VERSION "J35_6AT"

NS_ :

BS_:

BU_: PCM UNKNOWN

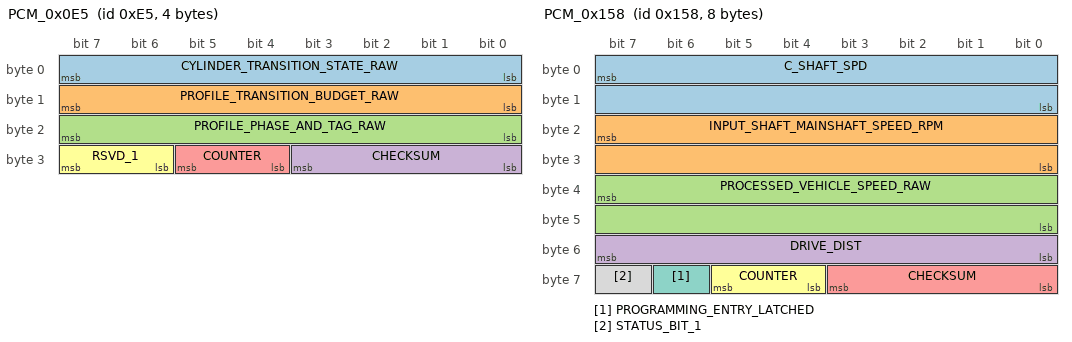
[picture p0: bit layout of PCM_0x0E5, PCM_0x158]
BO_ 229 PCM_0x0E5: 4 PCM
 SG_ CYLINDER_TRANSITION_STATE_RAW : 0|8@1+ (1,0) [0|255] ""  UNKNOWN
 SG_ PROFILE_TRANSITION_BUDGET_RAW : 8|8@1+ (1,0) [0|255] ""  UNKNOWN
 SG_ PROFILE_PHASE_AND_TAG_RAW : 16|8@1+ (1,0) [0|255] ""  UNKNOWN
 SG_ CHECKSUM : 24|4@1+ (1,0) [0|15] ""  UNKNOWN
 SG_ COUNTER : 28|2@1+ (1,0) [0|3] ""  UNKNOWN
 SG_ RSVD_1 : 30|2@1+ (1,0) [0|3] ""  UNKNOWN

BO_ 316 PCM_0x13C: 8 PCM
 SG_ TORQUE_ESTIMATE : 7|16@0- (1,0) [-32768|32767] "raw"  UNKNOWN
 SG_ TORQUE_TARGET : 23|16@0- (1,0) [-32768|32767] "raw"  UNKNOWN
 SG_ APP_SENSOR : 32|8@1+ (0.39215686274509803,0) [0|100] "%"  UNKNOWN
 SG_ TORQUE_STATE : 40|2@1+ (1,0) [0|3] ""  UNKNOWN
 SG_ RSVD_1 : 42|2@1+ (1,0) [0|3] ""  UNKNOWN
 SG_ RSVD_2 : 44|1@1+ (1,0) [0|1] ""  UNKNOWN
 SG_ FRAME_1AA_WINDOW_LATCH : 45|1@1+ (1,0) [0|1] ""  UNKNOWN
 SG_ START_PHASE_LATCH : 46|1@1+ (1,0) [0|1] ""  UNKNOWN
 SG_ DTC_STATUS_7_LATCH : 47|1@1+ (1,0) [0|1] ""  UNKNOWN
 SG_ RSVD_3 : 48|2@1+ (1,0) [0|3] ""  UNKNOWN
 SG_ CLUTCH_ENGAGEMENT_INFORMATION_CRUISE_CONTROL : 50|1@1+ (1,0) [0|1] ""  UNKNOWN
 SG_ CONTROL_GUARD_RAW : 51|1@1+ (1,0) [0|1] ""  UNKNOWN
 SG_ RSVD_4 : 52|4@1+ (1,0) [0|15] ""  UNKNOWN
 SG_ CHECKSUM : 56|4@1+ (1,0) [0|15] ""  UNKNOWN
 SG_ COUNTER : 60|2@1+ (1,0) [0|3] ""  UNKNOWN
 SG_ RSVD_5 : 62|1@1+ (1,0) [0|1] ""  UNKNOWN
 SG_ FRAME_1AA_INVALID_OR_FALLBACK_STATE_TBD : 63|1@1+ (1,0) [0|1] ""  UNKNOWN
VAL_ 316 CLUTCH_ENGAGEMENT_INFORMATION_CRUISE_CONTROL 0 "ON" 1 "OFF" ;
VAL_ 316 TORQUE_STATE 0 "NORMAL" 1 "VSA_CONTROL_CANDIDATE" 2 "FUEL_CUT" 3 "UNKNOWN" ;

BO_ 344 PCM_0x158: 8 PCM
 SG_ C_SHAFT_SPD : 7|16@0+ (0.01,0) [0|655.35] ""  UNKNOWN
 SG_ INPUT_SHAFT_MAINSHAFT_SPEED_RPM : 23|16@0+ (1,0) [0|65535] "raw"  UNKNOWN
 SG_ PROCESSED_VEHICLE_SPEED_RAW : 39|16@0+ (0.01,0) [0|655.35] ""  UNKNOWN
 SG_ DRIVE_DIST : 48|8@1+ (1,0) [0|255] "raw"  UNKNOWN
 SG_ CHECKSUM : 56|4@1+ (1,0) [0|15] ""  UNKNOWN
 SG_ COUNTER : 60|2@1+ (1,0) [0|3] ""  UNKNOWN
 SG_ PROGRAMMING_ENTRY_LATCHED : 62|1@1+ (1,0) [0|1] ""  UNKNOWN
 SG_ STATUS_BIT_1 : 63|1@1+ (1,0) [0|1] ""  UNKNOWN

BO_ 380 PCM_0x17C: 8 PCM
 SG_ APP_SENSOR : 0|8@1+ (0.39215686274509803,0) [0|100] "%"  UNKNOWN
 SG_ THROTTLE_ABOVE_IDLE_CODE : 8|8@1+ (0.4,0) [0|102] "deg"  UNKNOWN
 SG_ ENGINE_SPEED : 23|16@0+ (1,0) [0|65535] "rpm"  UNKNOWN
 SG_ BRAKE_SWITCH : 32|1@1+ (1,0) [0|1] ""  UNKNOWN
 SG_ CRUISE_CANCEL_EVENT : 33|1@1+ (1,0) [0|1] ""  UNKNOWN
 SG_ CRUISE_FAULT_SPEED_INHIBIT : 34|1@1+ (1,0) [0|1] ""  UNKNOWN
 SG_ CRUISE_ENGAGED : 35|1@1+ (1,0) [0|1] ""  UNKNOWN
 SG_ MIL : 36|1@1+ (1,0) [0|1] ""  UNKNOWN
 SG_ MIL_STATUS : 37|1@1+ (1,0) [0|1] ""  UNKNOWN
 SG_ CRUISE_INDICATOR : 38|1@1+ (1,0) [0|1] ""  UNKNOWN
 SG_ GAS_PEDAL_PRESSED : 39|1@1+ (1,0) [0|1] ""  UNKNOWN
 SG_ RSVD_1 : 40|2@1+ (1,0) [0|3] ""  UNKNOWN
 SG_ ACCEL_PEDAL_FAULT : 42|1@1+ (1,0) [0|1] ""  UNKNOWN
 SG_ RSVD_2 : 43|5@1+ (1,0) [0|31] ""  UNKNOWN
 SG_ RSVD_3 : 48|5@1+ (1,0) [0|31] ""  UNKNOWN
 SG_ CRUISE_BRAKE_SW_IDLE_STOP_SW : 53|1@1+ (1,0) [0|1] ""  UNKNOWN
 SG_ CRUISE_TRANS_REQUEST_WIRE : 54|2@1+ (1,0) [0|3] ""  UNKNOWN
 SG_ CHECKSUM : 56|4@1+ (1,0) [0|15] ""  UNKNOWN
 SG_ COUNTER : 60|2@1+ (1,0) [0|3] ""  UNKNOWN
 SG_ RSVD_4 : 62|1@1+ (1,0) [0|1] ""  UNKNOWN
 SG_ DTC_GROUP_WARNING_REQUESTED : 63|1@1+ (1,0) [0|1] ""  UNKNOWN
VAL_ 380 CRUISE_BRAKE_SW_IDLE_STOP_SW 0 "CLOSE" 1 "OPEN" ;
VAL_ 380 CRUISE_INDICATOR 0 "OFF" 1 "ON" ;
VAL_ 380 MIL_STATUS 0 "OFF" 1 "ON" ;
VAL_ 380 MIL 0 "OFF" 1 "ON" ;
VAL_ 380 BRAKE_SWITCH 0 "OFF" 1 "ON" ;

BO_ 392 PCM_0x188: 6 PCM
 SG_ SHIFT_CONTROL_CODE_A_RAW : 0|4@1+ (1,0) [0|15] ""  UNKNOWN
 SG_ TRANSMISSION_LATCH_RAW : 4|1@1+ (1,0) [0|1] ""  UNKNOWN
 SG_ CONDITIONED_GEAR_CODE_RAW : 5|3@1+ (1,0) [0|7] ""  UNKNOWN
 SG_ SHIFT_CONTROL_CODE_B_RAW : 8|3@1+ (1,0) [0|7] ""  UNKNOWN
 SG_ LED_C : 11|1@1+ (1,0) [0|1] ""  UNKNOWN
 SG_ LED_B : 12|1@1+ (1,0) [0|1] ""  UNKNOWN
 SG_ LED_A : 13|1@1+ (1,0) [0|1] ""  UNKNOWN
 SG_ SIGNED_CODE_SPILL_D1_RAW : 14|2@1+ (1,0) [0|3] ""  UNKNOWN
 SG_ SELECTOR_INDICATOR_RAW : 16|1@1+ (1,0) [0|1] ""  UNKNOWN
 SG_ TRANSMISSION_STATE_RAW : 17|1@1+ (1,0) [0|1] ""  UNKNOWN
 SG_ TRANSMISSION_QUALIFICATION_RAW : 18|1@1+ (1,0) [0|1] ""  UNKNOWN
 SG_ MANUAL_MODE_INDICATOR : 19|1@1+ (1,0) [0|1] ""  UNKNOWN
 SG_ INDICATOR_FAULT_RAW : 20|1@1+ (1,0) [0|1] ""  UNKNOWN
 SG_ TRANSMISSION_DIAGNOSTIC_LATCH_RAW : 21|1@1+ (1,0) [0|1] ""  UNKNOWN
 SG_ COMMUNICATION_STATUS_RAW : 22|1@1+ (1,0) [0|1] ""  UNKNOWN
 SG_ SHIFT_INDICATOR_CONTROL_RAW : 23|1@1+ (1,0) [0|1] ""  UNKNOWN
 SG_ A_T_P_SWITCH : 24|1@1+ (1,0) [0|1] ""  UNKNOWN
 SG_ A_T_R_SWITCH : 25|1@1+ (1,0) [0|1] ""  UNKNOWN
 SG_ A_T_N_SWITCH : 26|1@1+ (1,0) [0|1] ""  UNKNOWN
 SG_ A_T_D_SWITCH : 27|1@1+ (1,0) [0|1] ""  UNKNOWN
 SG_ RSVD_1 : 28|1@1+ (1,0) [0|1] ""  UNKNOWN
 SG_ A_T_D3_SWITCH : 29|1@1+ (1,0) [0|1] ""  UNKNOWN
 SG_ A_T_2_SWITCH_OR_A_T_L_SWITCH : 30|1@1+ (1,0) [0|1] ""  UNKNOWN
 SG_ A_T_1_SWITCH : 31|1@1+ (1,0) [0|1] ""  UNKNOWN
 SG_ SHIFT_POSITION_DISPLAY_CODE_RAW : 32|4@1+ (1,0) [0|15] ""  UNKNOWN
 SG_ A_T_S_SWITCH : 36|1@1+ (1,0) [0|1] ""  UNKNOWN
 SG_ SERVICE_RESET_ACK_RAW : 37|1@1+ (1,0) [0|1] ""  UNKNOWN
 SG_ SERVICE_DUE_RAW : 38|1@1+ (1,0) [0|1] ""  UNKNOWN
 SG_ SIGNED_CODE_SPILL_D4_RAW : 39|1@1+ (1,0) [0|1] ""  UNKNOWN
 SG_ CHECKSUM : 40|4@1+ (1,0) [0|15] ""  UNKNOWN
 SG_ COUNTER : 44|2@1+ (1,0) [0|3] ""  UNKNOWN
 SG_ QUALIFIED_TRANSMISSION_STATUS_RAW : 46|1@1+ (1,0) [0|1] ""  UNKNOWN
 SG_ RSVD_2 : 47|1@1+ (1,0) [0|1] ""  UNKNOWN
VAL_ 392 A_T_S_SWITCH 0 "OFF" 1 "ON" ;
VAL_ 392 A_T_1_SWITCH 0 "OFF" 1 "ON" ;
VAL_ 392 A_T_D3_SWITCH 0 "OFF" 1 "ON" ;
VAL_ 392 A_T_D_SWITCH 0 "OFF" 1 "ON" ;
VAL_ 392 A_T_N_SWITCH 0 "OFF" 1 "ON" ;
VAL_ 392 A_T_R_SWITCH 0 "OFF" 1 "ON" ;
VAL_ 392 A_T_P_SWITCH 0 "OFF" 1 "ON" ;
VAL_ 392 MANUAL_MODE_INDICATOR 0 "OFF" 1 "ON" ;
VAL_ 392 LED_A 0 "OFF" 1 "ON" ;
VAL_ 392 LED_B 0 "OFF" 1 "ON" ;
VAL_ 392 LED_C 0 "OFF" 1 "ON" ;

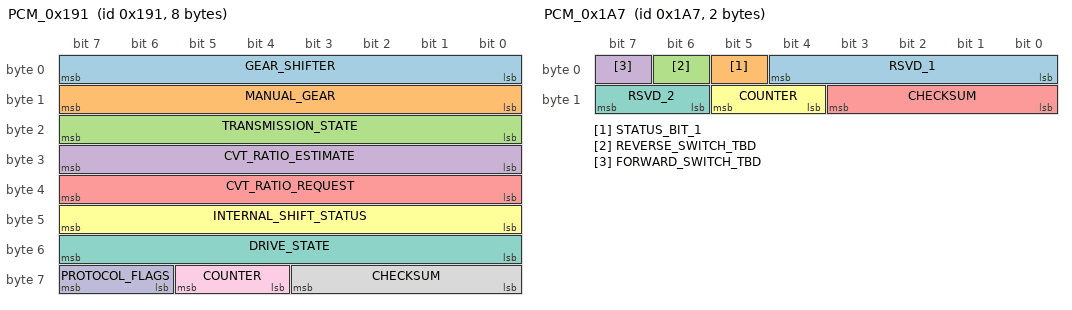
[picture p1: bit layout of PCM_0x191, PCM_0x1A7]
BO_ 401 PCM_0x191: 8 PCM
 SG_ GEAR_SHIFTER : 0|8@1+ (1,0) [0|255] ""  UNKNOWN
 SG_ MANUAL_GEAR : 8|8@1+ (1,0) [0|255] ""  UNKNOWN
 SG_ TRANSMISSION_STATE : 16|8@1+ (1,0) [0|255] ""  UNKNOWN
 SG_ CVT_RATIO_ESTIMATE : 24|8@1+ (1,0) [0|255] ""  UNKNOWN
 SG_ CVT_RATIO_REQUEST : 32|8@1+ (1,0) [0|255] ""  UNKNOWN
 SG_ INTERNAL_SHIFT_STATUS : 40|8@1+ (1,0) [0|255] ""  UNKNOWN
 SG_ DRIVE_STATE : 48|8@1+ (1,0) [0|255] ""  UNKNOWN
 SG_ CHECKSUM : 56|4@1+ (1,0) [0|15] ""  UNKNOWN
 SG_ COUNTER : 60|2@1+ (1,0) [0|3] ""  UNKNOWN
 SG_ PROTOCOL_FLAGS : 62|2@1+ (1,0) [0|3] ""  UNKNOWN

BO_ 423 PCM_0x1A7: 2 PCM
 SG_ RSVD_1 : 0|5@1+ (1,0) [0|31] ""  UNKNOWN
 SG_ STATUS_BIT_1 : 5|1@1+ (1,0) [0|1] ""  UNKNOWN
 SG_ REVERSE_SWITCH_TBD : 6|1@1+ (1,0) [0|1] ""  UNKNOWN
 SG_ FORWARD_SWITCH_TBD : 7|1@1+ (1,0) [0|1] ""  UNKNOWN
 SG_ CHECKSUM : 8|4@1+ (1,0) [0|15] ""  UNKNOWN
 SG_ COUNTER : 12|2@1+ (1,0) [0|3] ""  UNKNOWN
 SG_ RSVD_2 : 14|2@1+ (1,0) [0|3] ""  UNKNOWN

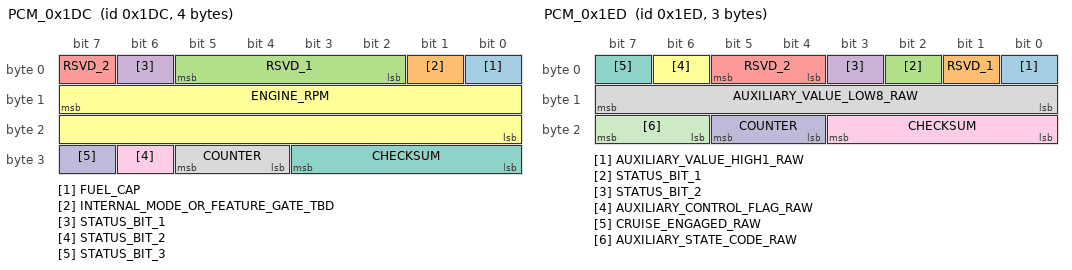
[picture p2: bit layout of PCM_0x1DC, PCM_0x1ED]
BO_ 476 PCM_0x1DC: 4 PCM
 SG_ FUEL_CAP : 0|1@1+ (1,0) [0|1] ""  UNKNOWN
 SG_ INTERNAL_MODE_OR_FEATURE_GATE_TBD : 1|1@1+ (1,0) [0|1] ""  UNKNOWN
 SG_ RSVD_1 : 2|4@1+ (1,0) [0|15] ""  UNKNOWN
 SG_ STATUS_BIT_1 : 6|1@1+ (1,0) [0|1] ""  UNKNOWN
 SG_ RSVD_2 : 7|1@1+ (1,0) [0|1] ""  UNKNOWN
 SG_ ENGINE_RPM : 15|16@0+ (1,0) [0|65535] "rpm"  UNKNOWN
 SG_ CHECKSUM : 24|4@1+ (1,0) [0|15] ""  UNKNOWN
 SG_ COUNTER : 28|2@1+ (1,0) [0|3] ""  UNKNOWN
 SG_ STATUS_BIT_2 : 30|1@1+ (1,0) [0|1] ""  UNKNOWN
 SG_ STATUS_BIT_3 : 31|1@1+ (1,0) [0|1] ""  UNKNOWN
VAL_ 476 FUEL_CAP 0 "CLOSE" 1 "OPEN" ;

BO_ 493 PCM_0x1ED: 3 PCM
 SG_ AUXILIARY_VALUE_HIGH1_RAW : 0|1@1+ (1,0) [0|1] ""  UNKNOWN
 SG_ RSVD_1 : 1|1@1+ (1,0) [0|1] ""  UNKNOWN
 SG_ STATUS_BIT_1 : 2|1@1+ (1,0) [0|1] ""  UNKNOWN
 SG_ STATUS_BIT_2 : 3|1@1+ (1,0) [0|1] ""  UNKNOWN
 SG_ RSVD_2 : 4|2@1+ (1,0) [0|3] ""  UNKNOWN
 SG_ AUXILIARY_CONTROL_FLAG_RAW : 6|1@1+ (1,0) [0|1] ""  UNKNOWN
 SG_ CRUISE_ENGAGED_RAW : 7|1@1+ (1,0) [0|1] ""  UNKNOWN
 SG_ AUXILIARY_VALUE_LOW8_RAW : 8|8@1+ (1,0) [0|255] ""  UNKNOWN
 SG_ CHECKSUM : 16|4@1+ (1,0) [0|15] ""  UNKNOWN
 SG_ COUNTER : 20|2@1+ (1,0) [0|3] ""  UNKNOWN
 SG_ AUXILIARY_STATE_CODE_RAW : 22|2@1+ (1,0) [0|3] ""  UNKNOWN

BO_ 800 BCM_0x320: 8 PCM
 SG_ RSVD_1 : 0|6@1+ (1,0) [0|63] ""  UNKNOWN
 SG_ ENGINE_STATE_CODE_TBD : 6|2@1+ (1,0) [0|3] ""  UNKNOWN
 SG_ STATUS_BIT_1 : 8|1@1+ (1,0) [0|1] ""  UNKNOWN
 SG_ STATUS_BIT_2 : 9|1@1+ (1,0) [0|1] ""  UNKNOWN
 SG_ RSVD_2 : 10|4@1+ (1,0) [0|15] ""  UNKNOWN
 SG_ STATUS_BIT_3 : 14|1@1+ (1,0) [0|1] ""  UNKNOWN
 SG_ RSVD_3 : 15|1@1+ (1,0) [0|1] ""  UNKNOWN
 SG_ UNKNOWN_1 : 16|3@1+ (1,0) [0|7] ""  UNKNOWN
 SG_ SIGNED_CAP_OUT_OF_DOMAIN_HIGH_BITS_B2_TBD : 19|3@1+ (1,0) [0|7] ""  UNKNOWN
 SG_ STATUS_BIT_4 : 22|1@1+ (1,0) [0|1] ""  UNKNOWN
 SG_ SIGNED_CAP_OUT_OF_DOMAIN_SIGN_BIT_B2_TBD : 23|1@1+ (1,0) [0|1] ""  UNKNOWN
 SG_ RSVD_4 : 24|8@1+ (1,0) [0|255] ""  UNKNOWN
 SG_ RSVD_5 : 32|7@1+ (1,0) [0|127] ""  UNKNOWN
 SG_ STATUS_BIT_5 : 39|1@1+ (1,0) [0|1] ""  UNKNOWN
 SG_ UNKNOWN_2 : 40|3@1+ (1,0) [0|7] ""  UNKNOWN
 SG_ UNKNOWN_3 : 43|3@1+ (1,0) [0|7] ""  UNKNOWN
 SG_ SIGNED_CAP_OUT_OF_DOMAIN_HIGH_BITS_B5_TBD : 46|2@1+ (1,0) [0|3] ""  UNKNOWN
 SG_ STATUS_BIT_6 : 48|1@1+ (1,0) [0|1] ""  UNKNOWN
 SG_ RSVD_6 : 49|2@1+ (1,0) [0|3] ""  UNKNOWN
 SG_ STATUS_BIT_7 : 51|1@1+ (1,0) [0|1] ""  UNKNOWN
 SG_ RSVD_7 : 52|4@1+ (1,0) [0|15] ""  UNKNOWN
 SG_ CHECKSUM : 56|4@1+ (1,0) [0|15] ""  UNKNOWN
 SG_ COUNTER : 60|2@1+ (1,0) [0|3] ""  UNKNOWN
 SG_ STATUS_BIT_8 : 62|1@1+ (1,0) [0|1] ""  UNKNOWN
 SG_ STATUS_BIT_9 : 63|1@1+ (1,0) [0|1] ""  UNKNOWN

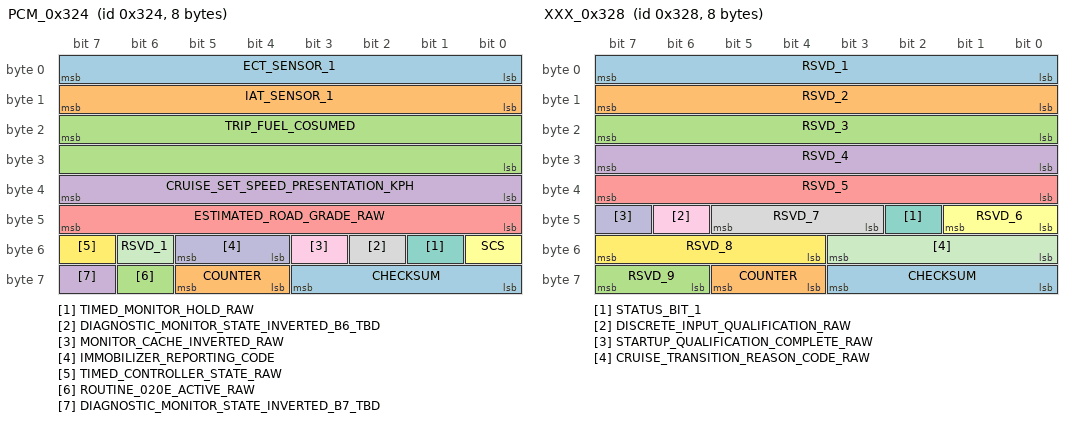
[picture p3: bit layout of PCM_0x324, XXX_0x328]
BO_ 804 PCM_0x324: 8 PCM
 SG_ ECT_SENSOR_1 : 0|8@1+ (1,-40) [-40|215] "degC"  UNKNOWN
 SG_ IAT_SENSOR_1 : 8|8@1+ (1,-40) [-40|215] "degC"  UNKNOWN
 SG_ TRIP_FUEL_COSUMED : 23|16@0+ (1,0) [0|65535] ""  UNKNOWN
 SG_ CRUISE_SET_SPEED_PRESENTATION_KPH : 32|8@1+ (1,0) [0|255] "raw"  UNKNOWN
 SG_ ESTIMATED_ROAD_GRADE_RAW : 40|8@1- (0.125,0) [-16|15.875] ""  UNKNOWN
 SG_ SCS : 48|1@1+ (1,0) [0|1] ""  UNKNOWN
 SG_ TIMED_MONITOR_HOLD_RAW : 49|1@1+ (1,0) [0|1] ""  UNKNOWN
 SG_ DIAGNOSTIC_MONITOR_STATE_INVERTED_B6_TBD : 50|1@1+ (1,0) [0|1] ""  UNKNOWN
 SG_ MONITOR_CACHE_INVERTED_RAW : 51|1@1+ (1,0) [0|1] ""  UNKNOWN
 SG_ IMMOBILIZER_REPORTING_CODE : 52|2@1+ (1,0) [0|3] ""  UNKNOWN
 SG_ RSVD_1 : 54|1@1+ (1,0) [0|1] ""  UNKNOWN
 SG_ TIMED_CONTROLLER_STATE_RAW : 55|1@1+ (1,0) [0|1] ""  UNKNOWN
 SG_ CHECKSUM : 56|4@1+ (1,0) [0|15] ""  UNKNOWN
 SG_ COUNTER : 60|2@1+ (1,0) [0|3] ""  UNKNOWN
 SG_ ROUTINE_020E_ACTIVE_RAW : 62|1@1+ (1,0) [0|1] ""  UNKNOWN
 SG_ DIAGNOSTIC_MONITOR_STATE_INVERTED_B7_TBD : 63|1@1+ (1,0) [0|1] ""  UNKNOWN
VAL_ 804 IMMOBILIZER_REPORTING_CODE 0 "COMPLETE_ACCEPTED" 1 "INCOMPLETE" 2 "COMPLETE_NOT_ACCEPTED" ;
VAL_ 804 SCS 0 "OPEN" 1 "SHORT" ;
VAL_ 804 IAT_SENSOR_1 255 "INVALID" ;
VAL_ 804 ECT_SENSOR_1 255 "INVALID" ;

BO_ 808 XXX_0x328: 8 PCM
 SG_ RSVD_1 : 0|8@1+ (1,0) [0|255] ""  UNKNOWN
 SG_ RSVD_2 : 8|8@1+ (1,0) [0|255] ""  UNKNOWN
 SG_ RSVD_3 : 16|8@1+ (1,0) [0|255] ""  UNKNOWN
 SG_ RSVD_4 : 24|8@1+ (1,0) [0|255] ""  UNKNOWN
 SG_ RSVD_5 : 32|8@1+ (1,0) [0|255] ""  UNKNOWN
 SG_ RSVD_6 : 40|2@1+ (1,0) [0|3] ""  UNKNOWN
 SG_ STATUS_BIT_1 : 42|1@1+ (1,0) [0|1] ""  UNKNOWN
 SG_ RSVD_7 : 43|3@1+ (1,0) [0|7] ""  UNKNOWN
 SG_ DISCRETE_INPUT_QUALIFICATION_RAW : 46|1@1+ (1,0) [0|1] ""  UNKNOWN
 SG_ STARTUP_QUALIFICATION_COMPLETE_RAW : 47|1@1+ (1,0) [0|1] ""  UNKNOWN
 SG_ CRUISE_TRANSITION_REASON_CODE_RAW : 48|4@1+ (1,0) [0|15] ""  UNKNOWN
 SG_ RSVD_8 : 52|4@1+ (1,0) [0|15] ""  UNKNOWN
 SG_ CHECKSUM : 56|4@1+ (1,0) [0|15] ""  UNKNOWN
 SG_ COUNTER : 60|2@1+ (1,0) [0|3] ""  UNKNOWN
 SG_ RSVD_9 : 62|2@1+ (1,0) [0|3] ""  UNKNOWN

BO_ 892 PCM_0x37C: 8 PCM
 SG_ UNKNOWN_1 : 0|8@1+ (1,0) [0|255] ""  UNKNOWN
 SG_ UNKNOWN_2 : 8|8@1+ (1,0) [0|255] ""  UNKNOWN
 SG_ UNKNOWN_3 : 16|8@1+ (1,0) [0|255] ""  UNKNOWN
 SG_ UNKNOWN_4 : 24|8@1+ (1,0) [0|255] ""  UNKNOWN
 SG_ RSVD_1 : 32|8@1+ (1,0) [0|255] ""  UNKNOWN
 SG_ UNKNOWN_5 : 40|7@1+ (1,0) [0|127] ""  UNKNOWN
 SG_ STATUS_BIT_1 : 47|1@1+ (1,0) [0|1] ""  UNKNOWN
 SG_ STATUS_BIT_2 : 48|1@1+ (1,0) [0|1] ""  UNKNOWN
 SG_ STATUS_BIT_3 : 49|1@1+ (1,0) [0|1] ""  UNKNOWN
 SG_ STATUS_BIT_4 : 50|1@1+ (1,0) [0|1] ""  UNKNOWN
 SG_ STATUS_BIT_5 : 51|1@1+ (1,0) [0|1] ""  UNKNOWN
 SG_ STATUS_BIT_6 : 52|1@1+ (1,0) [0|1] ""  UNKNOWN
 SG_ STATUS_BIT_7 : 53|1@1+ (1,0) [0|1] ""  UNKNOWN
 SG_ STATUS_BIT_8 : 54|1@1+ (1,0) [0|1] ""  UNKNOWN
 SG_ STATUS_BIT_9 : 55|1@1+ (1,0) [0|1] ""  UNKNOWN
 SG_ CHECKSUM : 56|4@1+ (1,0) [0|15] ""  UNKNOWN
 SG_ COUNTER : 60|2@1+ (1,0) [0|3] ""  UNKNOWN
 SG_ RSVD_2 : 62|1@1+ (1,0) [0|1] ""  UNKNOWN
 SG_ STATUS_BIT_10 : 63|1@1+ (1,0) [0|1] ""  UNKNOWN

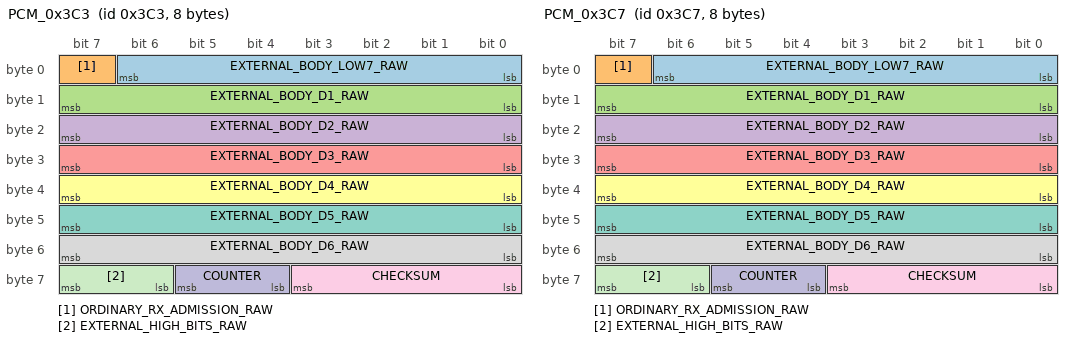
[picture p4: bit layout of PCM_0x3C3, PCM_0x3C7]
BO_ 963 PCM_0x3C3: 8 PCM
 SG_ EXTERNAL_BODY_LOW7_RAW : 0|7@1+ (1,0) [0|0] ""  UNKNOWN
 SG_ ORDINARY_RX_ADMISSION_RAW : 7|1@1+ (1,0) [0|0] ""  UNKNOWN
 SG_ EXTERNAL_BODY_D1_RAW : 8|8@1+ (1,0) [0|0] ""  UNKNOWN
 SG_ EXTERNAL_BODY_D2_RAW : 16|8@1+ (1,0) [0|0] ""  UNKNOWN
 SG_ EXTERNAL_BODY_D3_RAW : 24|8@1+ (1,0) [0|0] ""  UNKNOWN
 SG_ EXTERNAL_BODY_D4_RAW : 32|8@1+ (1,0) [0|0] ""  UNKNOWN
 SG_ EXTERNAL_BODY_D5_RAW : 40|8@1+ (1,0) [0|0] ""  UNKNOWN
 SG_ EXTERNAL_BODY_D6_RAW : 48|8@1+ (1,0) [0|0] ""  UNKNOWN
 SG_ CHECKSUM : 56|4@1+ (1,0) [0|0] ""  UNKNOWN
 SG_ COUNTER : 60|2@1+ (1,0) [0|0] ""  UNKNOWN
 SG_ EXTERNAL_HIGH_BITS_RAW : 62|2@1+ (1,0) [0|0] ""  UNKNOWN

BO_ 967 PCM_0x3C7: 8 PCM
 SG_ EXTERNAL_BODY_LOW7_RAW : 0|7@1+ (1,0) [0|0] ""  UNKNOWN
 SG_ ORDINARY_RX_ADMISSION_RAW : 7|1@1+ (1,0) [0|0] ""  UNKNOWN
 SG_ EXTERNAL_BODY_D1_RAW : 8|8@1+ (1,0) [0|0] ""  UNKNOWN
 SG_ EXTERNAL_BODY_D2_RAW : 16|8@1+ (1,0) [0|0] ""  UNKNOWN
 SG_ EXTERNAL_BODY_D3_RAW : 24|8@1+ (1,0) [0|0] ""  UNKNOWN
 SG_ EXTERNAL_BODY_D4_RAW : 32|8@1+ (1,0) [0|0] ""  UNKNOWN
 SG_ EXTERNAL_BODY_D5_RAW : 40|8@1+ (1,0) [0|0] ""  UNKNOWN
 SG_ EXTERNAL_BODY_D6_RAW : 48|8@1+ (1,0) [0|0] ""  UNKNOWN
 SG_ CHECKSUM : 56|4@1+ (1,0) [0|0] ""  UNKNOWN
 SG_ COUNTER : 60|2@1+ (1,0) [0|0] ""  UNKNOWN
 SG_ EXTERNAL_HIGH_BITS_RAW : 62|2@1+ (1,0) [0|0] ""  UNKNOWN

BO_ 983 PCM_0x3D7: 8 PCM
 SG_ MULTIPLEX_HEADER : 0|8@1+ (1,0) [0|255] ""  UNKNOWN
 SG_ RETAINED_BANK_A_CODE_WORD_0_PAGE_0 m0 : 15|16@0+ (1,0) [0|65535] ""  UNKNOWN
 SG_ RETAINED_BANK_A_CODE_WORD_0_PAGE_1 m1 : 15|16@0+ (1,0) [0|65535] ""  UNKNOWN
 SG_ RETAINED_BANK_A_CODE_WORD_1_PAGE_0 m0 : 31|16@0+ (1,0) [0|65535] ""  UNKNOWN
 SG_ RETAINED_BANK_A_CODE_WORD_1_PAGE_1 m1 : 31|16@0+ (1,0) [0|65535] ""  UNKNOWN
 SG_ RETAINED_BANK_A_CODE_WORD_2_PAGE_0 m0 : 47|16@0+ (1,0) [0|65535] ""  UNKNOWN
 SG_ RETAINED_BANK_A_CODE_WORD_2_PAGE_1 m1 : 47|16@0+ (1,0) [0|65535] ""  UNKNOWN
 SG_ CHECKSUM : 56|4@1+ (1,0) [0|15] ""  UNKNOWN
 SG_ COUNTER : 60|2@1+ (1,0) [0|3] ""  UNKNOWN
 SG_ PAGE_INDEX M : 62|1@1+ (1,0) [0|1] ""  UNKNOWN
 SG_ PROTOCOL_BIT7 : 63|1@1+ (1,0) [0|1] ""  UNKNOWN
VAL_ 983 PAGE_INDEX 0 "SLOTS0_TO2" 1 "SLOTS3_TO5" ;
SG_MUL_VAL_ 983 RETAINED_BANK_A_CODE_WORD_0_PAGE_0 PAGE_INDEX 0-0;
SG_MUL_VAL_ 983 RETAINED_BANK_A_CODE_WORD_0_PAGE_1 PAGE_INDEX 1-1;
SG_MUL_VAL_ 983 RETAINED_BANK_A_CODE_WORD_1_PAGE_0 PAGE_INDEX 0-0;
SG_MUL_VAL_ 983 RETAINED_BANK_A_CODE_WORD_1_PAGE_1 PAGE_INDEX 1-1;
SG_MUL_VAL_ 983 RETAINED_BANK_A_CODE_WORD_2_PAGE_0 PAGE_INDEX 0-0;
SG_MUL_VAL_ 983 RETAINED_BANK_A_CODE_WORD_2_PAGE_1 PAGE_INDEX 1-1;

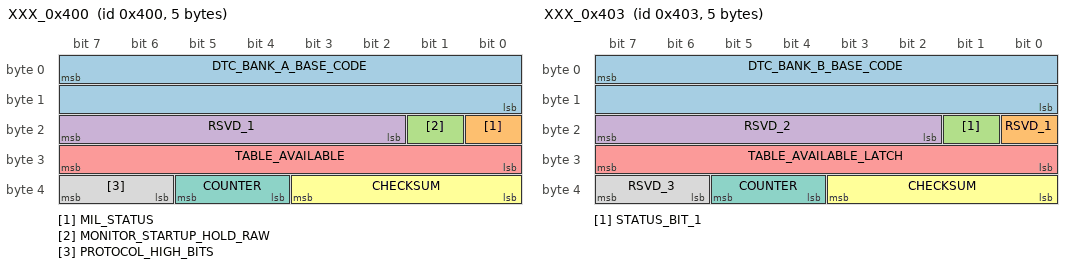
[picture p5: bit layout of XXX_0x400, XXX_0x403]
BO_ 1024 XXX_0x400: 5 PCM
 SG_ DTC_BANK_A_BASE_CODE : 7|16@0+ (1,0) [0|65535] ""  UNKNOWN
 SG_ MIL_STATUS : 16|1@1+ (1,0) [0|1] ""  UNKNOWN
 SG_ MONITOR_STARTUP_HOLD_RAW : 17|1@1+ (1,0) [0|1] ""  UNKNOWN
 SG_ RSVD_1 : 18|6@1+ (1,0) [0|63] ""  UNKNOWN
 SG_ TABLE_AVAILABLE : 24|8@1+ (1,0) [0|255] ""  UNKNOWN
 SG_ CHECKSUM : 32|4@1+ (1,0) [0|15] ""  UNKNOWN
 SG_ COUNTER : 36|2@1+ (1,0) [0|3] ""  UNKNOWN
 SG_ PROTOCOL_HIGH_BITS : 38|2@1+ (1,0) [0|3] ""  UNKNOWN
VAL_ 1024 MIL_STATUS 0 "OFF" 1 "ON" ;

BO_ 1027 XXX_0x403: 5 PCM
 SG_ DTC_BANK_B_BASE_CODE : 7|16@0+ (1,0) [0|65535] ""  UNKNOWN
 SG_ RSVD_1 : 16|1@1+ (1,0) [0|1] ""  UNKNOWN
 SG_ STATUS_BIT_1 : 17|1@1+ (1,0) [0|1] ""  UNKNOWN
 SG_ RSVD_2 : 18|6@1+ (1,0) [0|63] ""  UNKNOWN
 SG_ TABLE_AVAILABLE_LATCH : 24|8@1+ (1,0) [0|255] ""  UNKNOWN
 SG_ CHECKSUM : 32|4@1+ (1,0) [0|15] ""  UNKNOWN
 SG_ COUNTER : 36|2@1+ (1,0) [0|3] ""  UNKNOWN
 SG_ RSVD_3 : 38|2@1+ (1,0) [0|3] ""  UNKNOWN

BO_ 1036 XXX_0x40C: 8 PCM
 SG_ MULTIPLEX_PAGE M : 0|4@1+ (1,0) [0|15] ""  UNKNOWN
 SG_ MULTIPLEX_GROUP : 4|2@1+ (1,0) [0|3] ""  UNKNOWN
 SG_ DIAGNOSTIC_EVENT_STATE : 6|2@1+ (1,0) [0|3] ""  UNKNOWN
 SG_ RSVD_1 m0 : 8|8@1+ (1,0) [0|255] ""  UNKNOWN
 SG_ P01_VIN_CHARACTER_1_B1_RAW m1 : 8|8@1+ (1,0) [0|255] ""  UNKNOWN
 SG_ P02_VIN_CHARACTER_7_B1_RAW m2 : 8|8@1+ (1,0) [0|255] ""  UNKNOWN
 SG_ P03_VIN_CHARACTER_13_B1_RAW m3 : 8|8@1+ (1,0) [0|255] ""  UNKNOWN
 SG_ P04_VARIANTCONFIGBYTE1_B1_RAW m4 : 8|8@1+ (1,0) [0|255] ""  UNKNOWN
 SG_ P05_ENGINE_SPEED m5 : 15|16@0+ (0.25,0) [0|16383.75] "rpm"  UNKNOWN
 SG_ P06_IAT_SENSOR_VOLTAGE_B1_RAW m6 : 8|8@1+ (0.0196078431372549,0) [0|5] "V"  UNKNOWN
 SG_ P07_VEHICLE_SPEED_B1_RAW m7 : 8|8@1+ (1,0) [0|255] "km/h"  UNKNOWN
 SG_ P08_APP_SENSOR m8 : 15|16@0+ (0.005,0) [0|327.675] "%"  UNKNOWN
 SG_ P09_TARGET_TH_VLV m9 : 15|16@0+ (0.005,0) [0|327.675] "deg"  UNKNOWN
 SG_ P0A_AF_SENSOR_B1 m10 : 15|16@0+ (1,0) [0|65535] ""  UNKNOWN
 SG_ UNKNOWN_1 m11 : 8|8@1+ (1,0) [0|255] ""  UNKNOWN
 SG_ P0C_AF_FB_ST_FUEL_TRIM_B2 m12 : 8|8@1+ (0.0078125,0) [0|1.9921875] "ratio"  UNKNOWN
 SG_ P0D_EGR_VALVE_POSITION_SENSOR_EGR_VLS m13 : 8|8@1+ (1,0) [0|255] ""  UNKNOWN
 SG_ P0E_MASSAIRFLOW m14 : 15|16@0+ (0.01,0) [0|655.35] "g/s"  UNKNOWN
 SG_ P0F_FUELTANKLEVELINPUT_B1_RAW m15 : 8|8@1+ (0.39215686274509803,0) [0|100] "%"  UNKNOWN
 SG_ P00_DIAGNOSTIC_EVENT_CACHE_WORD m0 : 23|16@0+ (1,0) [0|65535] ""  UNKNOWN
 SG_ P01_VIN_CHARACTER_2_B2_RAW m1 : 16|8@1+ (1,0) [0|255] ""  UNKNOWN
 SG_ P02_VIN_CHARACTER_8_B2_RAW m2 : 16|8@1+ (1,0) [0|255] ""  UNKNOWN
 SG_ P03_VIN_CHARACTER_14_B2_RAW m3 : 16|8@1+ (1,0) [0|255] ""  UNKNOWN
 SG_ P04_VARIANTCONFIGBYTE2_B2_RAW m4 : 16|8@1+ (1,0) [0|255] ""  UNKNOWN
 SG_ P06_INTAKE_AIR_TEMPERATURE_B2_RAW m6 : 16|8@1+ (1,-40) [-40|215] "degC"  UNKNOWN
 SG_ P07_CALCULATEDENGINELOAD_B2_RAW m7 : 16|8@1+ (0.39215686274509803,0) [0|100] "%"  UNKNOWN
 SG_ P0B_HO2S_S2_B1 m11 : 16|8@1+ (0.0196078431372549,0) [0|5] "V"  UNKNOWN
 SG_ P0C_AF_FB_AVE_LT_FUEL_TRIM_B2 m12 : 16|8@1+ (0.0078125,0) [0|1.9921875] "ratio"  UNKNOWN
 SG_ RSVD_2 m13 : 16|8@1+ (1,0) [0|255] ""  UNKNOWN
 SG_ RSVD_3 m15 : 16|8@1+ (1,0) [0|255] ""  UNKNOWN
 SG_ P01_VIN_CHARACTER_3_B3_RAW m1 : 24|8@1+ (1,0) [0|255] ""  UNKNOWN
 SG_ P02_VIN_CHARACTER_9_B3_RAW m2 : 24|8@1+ (1,0) [0|255] ""  UNKNOWN
 SG_ P03_VIN_CHARACTER_15_B3_RAW m3 : 24|8@1+ (1,0) [0|255] ""  UNKNOWN
 SG_ P04_VARIANTCONFIGBYTE3_B3_RAW m4 : 24|8@1+ (1,0) [0|255] ""  UNKNOWN
 SG_ P05_THROTTLEPOSITION_B3_RAW m5 : 24|8@1+ (0.39215686274509803,0) [0|100] "%"  UNKNOWN
 SG_ P06_MAP_SENSOR_VOLTAGE_B3_RAW m6 : 24|8@1+ (0.0196078431372549,0) [0|5] "V"  UNKNOWN
 SG_ P07_SPARK_ADVANCE m7 : 24|8@1+ (0.5,-64) [-64|63.5] "deg"  UNKNOWN
 SG_ P08_TP_SENSOR_1 m8 : 24|8@1+ (0.0196078431372549,0) [0|5] "V"  UNKNOWN
 SG_ UNKNOWN_2 m9 : 24|8@1+ (1,0) [0|255] ""  UNKNOWN
 SG_ P0A_AF_LAMBDA_B1 m10 : 31|16@0+ (3.0517578125e-05,0) [0|1.999969482421875] "ratio"  UNKNOWN
 SG_ P0B_AF_SENSOR_B2 m11 : 31|16@0+ (1,0) [0|65535] ""  UNKNOWN
 SG_ UNKNOWN_3 m12 : 24|8@1+ (1,0) [0|255] ""  UNKNOWN
 SG_ RSVD_4 m13 : 24|8@1+ (1,0) [0|255] ""  UNKNOWN
 SG_ RSVD_5 m14 : 24|8@1+ (1,0) [0|255] ""  UNKNOWN
 SG_ RSVD_6 m15 : 24|8@1+ (1,0) [0|255] ""  UNKNOWN
 SG_ UNKNOWN_4 m0 : 32|8@1+ (1,0) [0|255] ""  UNKNOWN
 SG_ P01_VIN_CHARACTER_4_B4_RAW m1 : 32|8@1+ (1,0) [0|255] ""  UNKNOWN
 SG_ P02_VIN_CHARACTER_10_B4_RAW m2 : 32|8@1+ (1,0) [0|255] ""  UNKNOWN
 SG_ P03_VIN_CHARACTER_16_B4_RAW m3 : 32|8@1+ (1,0) [0|255] ""  UNKNOWN
 SG_ P04_VARIANTCONFIGBYTE4_B4_RAW m4 : 32|8@1+ (1,0) [0|255] ""  UNKNOWN
 SG_ P05_RELATIVETHROTTLEPOSITION_B4_RAW m5 : 32|8@1+ (0.39215686274509803,0) [0|100] "%"  UNKNOWN
 SG_ P06_MANIFOLD_ABSOLUTE_PRESSURE_B4_RAW m6 : 32|8@1+ (1,0) [0|255] "kPa"  UNKNOWN
 SG_ P07_CONTROL_MODULE_VOLTAGE_DECIVOLT_RAW m7 : 32|8@1+ (0.1,0) [0|25.5] "V"  UNKNOWN
 SG_ P08_TP_SENSOR_2 m8 : 32|8@1+ (0.0196078431372549,0) [0|5] "V"  UNKNOWN
 SG_ UNKNOWN_5 m9 : 32|8@1+ (1,0) [0|255] ""  UNKNOWN
 SG_ P0C_HO2S_S2_B2 m12 : 32|8@1+ (0.0196078431372549,0) [0|5] "V"  UNKNOWN
 SG_ P0D_MAF_SENSOR m13 : 32|8@1+ (0.0196078431372549,0) [0|5] "V"  UNKNOWN
 SG_ P0E_RUNTIMESINCEENGINESTART m14 : 39|16@0+ (1,0) [0|65535] "s"  UNKNOWN
 SG_ RSVD_7 m15 : 32|8@1+ (1,0) [0|255] ""  UNKNOWN
 SG_ RSVD_8 m0 : 40|8@1+ (1,0) [0|255] ""  UNKNOWN
 SG_ P01_VIN_CHARACTER_5_B5_RAW m1 : 40|8@1+ (1,0) [0|255] ""  UNKNOWN
 SG_ P02_VIN_CHARACTER_11_B5_RAW m2 : 40|8@1+ (1,0) [0|255] ""  UNKNOWN
 SG_ P03_VIN_CHARACTER_17_B5_RAW m3 : 40|8@1+ (1,0) [0|255] ""  UNKNOWN
 SG_ P04_VARIANTCONFIGBYTE5_B5_RAW m4 : 40|8@1+ (1,0) [0|255] ""  UNKNOWN
 SG_ P05_ECT_SENSOR_VOLTAGE_B5_RAW m5 : 40|8@1+ (0.0196078431372549,0) [0|5] "V"  UNKNOWN
 SG_ P06_BARO_SENSOR_VOLTAGE_B5_RAW m6 : 40|8@1+ (0.0196078431372549,0) [0|5] "V"  UNKNOWN
 SG_ P07_APP_SENSOR_A_VOLTAGE_B5_RAW m7 : 40|8@1+ (0.0196078431372549,0) [0|5] "V"  UNKNOWN
 SG_ P08_THROTTLE_VLV m8 : 47|16@0+ (0.005,0) [0|327.675] "deg"  UNKNOWN
 SG_ P09_IDLE_TARGET_TH m9 : 47|16@0+ (0.005,0) [0|327.675] "deg"  UNKNOWN
 SG_ P0A_SHORTTERMFUELTRIMBANK1_B5_RAW m10 : 40|8@1+ (0.78125,-100) [-100|99.21875] "%"  UNKNOWN
 SG_ P0B_AF_LAMBDA_B2 m11 : 47|16@0+ (3.0517578125e-05,0) [0|1.999969482421875] "ratio"  UNKNOWN
 SG_ P0C_F_INJECTOR m12 : 47|16@0+ (0.004,0) [0|262.14] "ms"  UNKNOWN
 SG_ RSVD_9 m13 : 40|8@1+ (1,0) [0|255] ""  UNKNOWN
 SG_ RSVD_10 m15 : 40|8@1+ (1,0) [0|255] ""  UNKNOWN
 SG_ RSVD_11 m0 : 48|8@1+ (1,0) [0|255] ""  UNKNOWN
 SG_ P01_VIN_CHARACTER_6_B6_RAW m1 : 48|8@1+ (1,0) [0|255] ""  UNKNOWN
 SG_ P02_VIN_CHARACTER_12_B6_RAW m2 : 48|8@1+ (1,0) [0|255] ""  UNKNOWN
 SG_ UNKNOWN_6 m3 : 48|8@1+ (1,0) [0|255] ""  UNKNOWN
 SG_ RSVD_12 m4 : 48|8@1+ (1,0) [0|255] ""  UNKNOWN
 SG_ P05_ENGINE_COOLANT_TEMPERATURE_B6_RAW m5 : 48|8@1+ (1,-40) [-40|215] "degC"  UNKNOWN
 SG_ P06_BAROMETRICPRESSURE_B6_RAW m6 : 48|8@1+ (1,0) [0|255] "kPa"  UNKNOWN
 SG_ P07_APP_SENSOR_B_VOLTAGE_B6_RAW m7 : 48|8@1+ (0.0196078431372549,0) [0|5] "V"  UNKNOWN
 SG_ P0A_LONGTERMFUELTRIMBANK1_B6_RAW m10 : 48|8@1+ (0.78125,-100) [-100|99.21875] "%"  UNKNOWN
 SG_ RSVD_13 m13 : 48|8@1+ (1,0) [0|255] ""  UNKNOWN
 SG_ P0E_COMMANDEDEVAPORATIVEPURGE_B6_RAW m14 : 48|8@1+ (0.39215686274509803,0) [0|100] "%"  UNKNOWN
 SG_ RSVD_14 m15 : 48|8@1+ (1,0) [0|255] ""  UNKNOWN
 SG_ CHECKSUM : 56|4@1+ (1,0) [0|15] ""  UNKNOWN
 SG_ COUNTER : 60|2@1+ (1,0) [0|3] ""  UNKNOWN
 SG_ DIAGNOSTIC_STATUS_FLAG6 : 62|1@1+ (1,0) [0|1] ""  UNKNOWN
 SG_ DIAGNOSTIC_STATUS_FLAG7 : 63|1@1+ (1,0) [0|1] ""  UNKNOWN
SG_MUL_VAL_ 1036 RSVD_1 MULTIPLEX_PAGE 0-0;
SG_MUL_VAL_ 1036 P01_VIN_CHARACTER_1_B1_RAW MULTIPLEX_PAGE 1-1;
SG_MUL_VAL_ 1036 P02_VIN_CHARACTER_7_B1_RAW MULTIPLEX_PAGE 2-2;
SG_MUL_VAL_ 1036 P03_VIN_CHARACTER_13_B1_RAW MULTIPLEX_PAGE 3-3;
SG_MUL_VAL_ 1036 P04_VARIANTCONFIGBYTE1_B1_RAW MULTIPLEX_PAGE 4-4;
SG_MUL_VAL_ 1036 P05_ENGINE_SPEED MULTIPLEX_PAGE 5-5;
SG_MUL_VAL_ 1036 P06_IAT_SENSOR_VOLTAGE_B1_RAW MULTIPLEX_PAGE 6-6;
SG_MUL_VAL_ 1036 P07_VEHICLE_SPEED_B1_RAW MULTIPLEX_PAGE 7-7;
SG_MUL_VAL_ 1036 P08_APP_SENSOR MULTIPLEX_PAGE 8-8;
SG_MUL_VAL_ 1036 P09_TARGET_TH_VLV MULTIPLEX_PAGE 9-9;
SG_MUL_VAL_ 1036 P0A_AF_SENSOR_B1 MULTIPLEX_PAGE 10-10;
SG_MUL_VAL_ 1036 UNKNOWN_1 MULTIPLEX_PAGE 11-11;
SG_MUL_VAL_ 1036 P0C_AF_FB_ST_FUEL_TRIM_B2 MULTIPLEX_PAGE 12-12;
SG_MUL_VAL_ 1036 P0D_EGR_VALVE_POSITION_SENSOR_EGR_VLS MULTIPLEX_PAGE 13-13;
SG_MUL_VAL_ 1036 P0E_MASSAIRFLOW MULTIPLEX_PAGE 14-14;
SG_MUL_VAL_ 1036 P0F_FUELTANKLEVELINPUT_B1_RAW MULTIPLEX_PAGE 15-15;
SG_MUL_VAL_ 1036 P00_DIAGNOSTIC_EVENT_CACHE_WORD MULTIPLEX_PAGE 0-0;
SG_MUL_VAL_ 1036 P01_VIN_CHARACTER_2_B2_RAW MULTIPLEX_PAGE 1-1;
SG_MUL_VAL_ 1036 P02_VIN_CHARACTER_8_B2_RAW MULTIPLEX_PAGE 2-2;
SG_MUL_VAL_ 1036 P03_VIN_CHARACTER_14_B2_RAW MULTIPLEX_PAGE 3-3;
SG_MUL_VAL_ 1036 P04_VARIANTCONFIGBYTE2_B2_RAW MULTIPLEX_PAGE 4-4;
SG_MUL_VAL_ 1036 P06_INTAKE_AIR_TEMPERATURE_B2_RAW MULTIPLEX_PAGE 6-6;
SG_MUL_VAL_ 1036 P07_CALCULATEDENGINELOAD_B2_RAW MULTIPLEX_PAGE 7-7;
SG_MUL_VAL_ 1036 P0B_HO2S_S2_B1 MULTIPLEX_PAGE 11-11;
SG_MUL_VAL_ 1036 P0C_AF_FB_AVE_LT_FUEL_TRIM_B2 MULTIPLEX_PAGE 12-12;
SG_MUL_VAL_ 1036 RSVD_2 MULTIPLEX_PAGE 13-13;
SG_MUL_VAL_ 1036 RSVD_3 MULTIPLEX_PAGE 15-15;
SG_MUL_VAL_ 1036 P01_VIN_CHARACTER_3_B3_RAW MULTIPLEX_PAGE 1-1;
SG_MUL_VAL_ 1036 P02_VIN_CHARACTER_9_B3_RAW MULTIPLEX_PAGE 2-2;
SG_MUL_VAL_ 1036 P03_VIN_CHARACTER_15_B3_RAW MULTIPLEX_PAGE 3-3;
SG_MUL_VAL_ 1036 P04_VARIANTCONFIGBYTE3_B3_RAW MULTIPLEX_PAGE 4-4;
SG_MUL_VAL_ 1036 P05_THROTTLEPOSITION_B3_RAW MULTIPLEX_PAGE 5-5;
SG_MUL_VAL_ 1036 P06_MAP_SENSOR_VOLTAGE_B3_RAW MULTIPLEX_PAGE 6-6;
SG_MUL_VAL_ 1036 P07_SPARK_ADVANCE MULTIPLEX_PAGE 7-7;
SG_MUL_VAL_ 1036 P08_TP_SENSOR_1 MULTIPLEX_PAGE 8-8;
SG_MUL_VAL_ 1036 UNKNOWN_2 MULTIPLEX_PAGE 9-9;
SG_MUL_VAL_ 1036 P0A_AF_LAMBDA_B1 MULTIPLEX_PAGE 10-10;
SG_MUL_VAL_ 1036 P0B_AF_SENSOR_B2 MULTIPLEX_PAGE 11-11;
SG_MUL_VAL_ 1036 UNKNOWN_3 MULTIPLEX_PAGE 12-12;
SG_MUL_VAL_ 1036 RSVD_4 MULTIPLEX_PAGE 13-13;
SG_MUL_VAL_ 1036 RSVD_5 MULTIPLEX_PAGE 14-14;
SG_MUL_VAL_ 1036 RSVD_6 MULTIPLEX_PAGE 15-15;
SG_MUL_VAL_ 1036 UNKNOWN_4 MULTIPLEX_PAGE 0-0;
SG_MUL_VAL_ 1036 P01_VIN_CHARACTER_4_B4_RAW MULTIPLEX_PAGE 1-1;
SG_MUL_VAL_ 1036 P02_VIN_CHARACTER_10_B4_RAW MULTIPLEX_PAGE 2-2;
SG_MUL_VAL_ 1036 P03_VIN_CHARACTER_16_B4_RAW MULTIPLEX_PAGE 3-3;
SG_MUL_VAL_ 1036 P04_VARIANTCONFIGBYTE4_B4_RAW MULTIPLEX_PAGE 4-4;
SG_MUL_VAL_ 1036 P05_RELATIVETHROTTLEPOSITION_B4_RAW MULTIPLEX_PAGE 5-5;
SG_MUL_VAL_ 1036 P06_MANIFOLD_ABSOLUTE_PRESSURE_B4_RAW MULTIPLEX_PAGE 6-6;
SG_MUL_VAL_ 1036 P07_CONTROL_MODULE_VOLTAGE_DECIVOLT_RAW MULTIPLEX_PAGE 7-7;
SG_MUL_VAL_ 1036 P08_TP_SENSOR_2 MULTIPLEX_PAGE 8-8;
SG_MUL_VAL_ 1036 UNKNOWN_5 MULTIPLEX_PAGE 9-9;
SG_MUL_VAL_ 1036 P0C_HO2S_S2_B2 MULTIPLEX_PAGE 12-12;
SG_MUL_VAL_ 1036 P0D_MAF_SENSOR MULTIPLEX_PAGE 13-13;
SG_MUL_VAL_ 1036 P0E_RUNTIMESINCEENGINESTART MULTIPLEX_PAGE 14-14;
SG_MUL_VAL_ 1036 RSVD_7 MULTIPLEX_PAGE 15-15;
SG_MUL_VAL_ 1036 RSVD_8 MULTIPLEX_PAGE 0-0;
SG_MUL_VAL_ 1036 P01_VIN_CHARACTER_5_B5_RAW MULTIPLEX_PAGE 1-1;
SG_MUL_VAL_ 1036 P02_VIN_CHARACTER_11_B5_RAW MULTIPLEX_PAGE 2-2;
SG_MUL_VAL_ 1036 P03_VIN_CHARACTER_17_B5_RAW MULTIPLEX_PAGE 3-3;
SG_MUL_VAL_ 1036 P04_VARIANTCONFIGBYTE5_B5_RAW MULTIPLEX_PAGE 4-4;
SG_MUL_VAL_ 1036 P05_ECT_SENSOR_VOLTAGE_B5_RAW MULTIPLEX_PAGE 5-5;
SG_MUL_VAL_ 1036 P06_BARO_SENSOR_VOLTAGE_B5_RAW MULTIPLEX_PAGE 6-6;
SG_MUL_VAL_ 1036 P07_APP_SENSOR_A_VOLTAGE_B5_RAW MULTIPLEX_PAGE 7-7;
SG_MUL_VAL_ 1036 P08_THROTTLE_VLV MULTIPLEX_PAGE 8-8;
SG_MUL_VAL_ 1036 P09_IDLE_TARGET_TH MULTIPLEX_PAGE 9-9;
SG_MUL_VAL_ 1036 P0A_SHORTTERMFUELTRIMBANK1_B5_RAW MULTIPLEX_PAGE 10-10;
SG_MUL_VAL_ 1036 P0B_AF_LAMBDA_B2 MULTIPLEX_PAGE 11-11;
SG_MUL_VAL_ 1036 P0C_F_INJECTOR MULTIPLEX_PAGE 12-12;
SG_MUL_VAL_ 1036 RSVD_9 MULTIPLEX_PAGE 13-13;
SG_MUL_VAL_ 1036 RSVD_10 MULTIPLEX_PAGE 15-15;
SG_MUL_VAL_ 1036 RSVD_11 MULTIPLEX_PAGE 0-0;
SG_MUL_VAL_ 1036 P01_VIN_CHARACTER_6_B6_RAW MULTIPLEX_PAGE 1-1;
SG_MUL_VAL_ 1036 P02_VIN_CHARACTER_12_B6_RAW MULTIPLEX_PAGE 2-2;
SG_MUL_VAL_ 1036 UNKNOWN_6 MULTIPLEX_PAGE 3-3;
SG_MUL_VAL_ 1036 RSVD_12 MULTIPLEX_PAGE 4-4;
SG_MUL_VAL_ 1036 P05_ENGINE_COOLANT_TEMPERATURE_B6_RAW MULTIPLEX_PAGE 5-5;
SG_MUL_VAL_ 1036 P06_BAROMETRICPRESSURE_B6_RAW MULTIPLEX_PAGE 6-6;
SG_MUL_VAL_ 1036 P07_APP_SENSOR_B_VOLTAGE_B6_RAW MULTIPLEX_PAGE 7-7;
SG_MUL_VAL_ 1036 P0A_LONGTERMFUELTRIMBANK1_B6_RAW MULTIPLEX_PAGE 10-10;
SG_MUL_VAL_ 1036 RSVD_13 MULTIPLEX_PAGE 13-13;
SG_MUL_VAL_ 1036 P0E_COMMANDEDEVAPORATIVEPURGE_B6_RAW MULTIPLEX_PAGE 14-14;
SG_MUL_VAL_ 1036 RSVD_14 MULTIPLEX_PAGE 15-15;

BO_ 1039 XXX_0x40F: 8 PCM
 SG_ MULTIPLEX_PAGE M : 0|4@1+ (1,0) [0|15] ""  UNKNOWN
 SG_ MULTIPLEX_GROUP : 4|2@1+ (1,0) [0|3] ""  UNKNOWN
 SG_ DIAGNOSTIC_EVENT_STATE : 6|2@1+ (1,0) [0|3] ""  UNKNOWN
 SG_ UNKNOWN_1 m0 : 8|8@1+ (1,0) [0|255] ""  UNKNOWN
 SG_ P01_CONFIG_BYTE_1_RAW m1 : 8|8@1+ (1,0) [0|255] ""  UNKNOWN
 SG_ P02_ENGINE_SPEED m2 : 8|8@1+ (50,0) [0|12750] "rpm"  UNKNOWN
 SG_ P03_ENGINE_COOLANT_TEMPERATURE m3 : 8|8@1+ (1,-40) [-40|215] "degC"  UNKNOWN
 SG_ P04_BARO_SENSOR_V m4 : 8|8@1+ (0.0196,0) [0|4.998] "V"  UNKNOWN
 SG_ P05_INPUT_SHAFT_MAINSHAFT_SPEED_RPM m5 : 15|16@0+ (1,0) [0|65535] "rpm"  UNKNOWN
 SG_ P06_A_T_C_P_C_SOL_VLV_A_ACTUAL m6 : 8|8@1+ (0.005,0) [0|1.2750000000000001] "A"  UNKNOWN
 SG_ P07_LINE_PRESSURE_SOL_VLV_A m7 : 8|1@1+ (1,0) [0|1] ""  UNKNOWN
 SG_ RSVD_1 m8 : 8|8@1+ (1,0) [0|255] ""  UNKNOWN
 SG_ P07_SHIFT_SOLENOID_VALVE_G m7 : 9|1@1+ (1,0) [0|1] ""  UNKNOWN
 SG_ P07_SHIFT_SOLENOID_VALVE_F m7 : 10|1@1+ (1,0) [0|1] ""  UNKNOWN
 SG_ P07_A_T_SHIFT_SOL_VLV_E m7 : 11|1@1+ (1,0) [0|1] ""  UNKNOWN
 SG_ P07_A_T_SHIFT_SOL_VLV_D m7 : 12|1@1+ (1,0) [0|1] ""  UNKNOWN
 SG_ P07_A_T_SHIFT_SOL_VLV_C m7 : 13|1@1+ (1,0) [0|1] ""  UNKNOWN
 SG_ P07_A_T_SHIFT_SOL_VLV_B m7 : 14|1@1+ (1,0) [0|1] ""  UNKNOWN
 SG_ P07_A_T_SHIFT_SOL_VLV_A m7 : 15|1@1+ (1,0) [0|1] ""  UNKNOWN
 SG_ UNKNOWN_2 m0 : 23|16@0+ (1,0) [0|65535] ""  UNKNOWN
 SG_ P01_CONFIG_BYTE_2_RAW m1 : 16|8@1+ (1,0) [0|255] ""  UNKNOWN
 SG_ P02_OUTPUT_SHAFT_COUNTER_SHAFT_SPEED m2 : 16|8@1+ (1,0) [0|255] "km/h"  UNKNOWN
 SG_ P03_BATTERY_VOLTAGE m3 : 16|8@1+ (0.1,0) [0|25.5] "V"  UNKNOWN
 SG_ P04_ATMOSPHERIC_PRESSURE m4 : 16|8@1+ (1,0) [0|255] "kPa"  UNKNOWN
 SG_ P06_A_T_C_P_C_SOL_VLV_B_COMMAND m6 : 16|8@1+ (0.005,0) [0|1.2750000000000001] "A"  UNKNOWN
 SG_ P07_ATF_TEMP_SENSOR_V m7 : 16|8@1+ (0.0196,0) [0|4.998] "V"  UNKNOWN
 SG_ RSVD_2 m8 : 16|8@1+ (1,0) [0|255] ""  UNKNOWN
 SG_ P01_CONFIG_BYTE_3_RAW m1 : 24|8@1+ (1,0) [0|255] ""  UNKNOWN
 SG_ P02_INPUT_SHAFT_MAINSHAFT_SPEED m2 : 24|8@1+ (1,0) [0|255] "km/h"  UNKNOWN
 SG_ P03_SHIFT_CONTROL m3 : 24|8@1+ (1,0) [0|255] ""  UNKNOWN
 SG_ P04_ENGINE_SPEED m4 : 31|16@0+ (1,0) [0|65535] "rpm"  UNKNOWN
 SG_ P05_APP_SENSOR m5 : 24|8@1+ (0.5,0) [0|127.5] "%"  UNKNOWN
 SG_ P06_A_T_C_P_C_SOL_VLV_B_ACTUAL m6 : 24|8@1+ (0.005,0) [0|1.2750000000000001] "A"  UNKNOWN
 SG_ P07_ATF_TEMPERATURE m7 : 24|8@1+ (1,-40) [-40|215] "degC"  UNKNOWN
 SG_ RSVD_3 m8 : 24|8@1+ (1,0) [0|255] ""  UNKNOWN
 SG_ UNKNOWN_3 m0 : 32|8@1+ (1,0) [0|255] ""  UNKNOWN
 SG_ P01_CONFIG_BYTE_4_RAW m1 : 32|8@1+ (1,0) [0|255] ""  UNKNOWN
 SG_ P02_TP_SENSOR_1 m2 : 32|8@1+ (0.0196,0) [0|4.998] "V"  UNKNOWN
 SG_ UNKNOWN_4 m3 : 32|8@1+ (1,0) [0|255] ""  UNKNOWN
 SG_ P05_APP_SENSOR_A_V m5 : 32|8@1+ (0.0196,0) [0|4.998] "V"  UNKNOWN
 SG_ P06_A_T_C_P_C_SOL_VLV_C_COMMAND m6 : 32|8@1+ (0.005,0) [0|1.2750000000000001] "A"  UNKNOWN
 SG_ P07_A_T_C_P_C_SOL_VLV_D_ACTUAL m7 : 32|8@1+ (0.005,0) [0|1.2750000000000001] "A"  UNKNOWN
 SG_ RSVD_4 m8 : 32|8@1+ (1,0) [0|255] ""  UNKNOWN
 SG_ RSVD_5 m0 : 47|16@0+ (1,0) [0|65535] ""  UNKNOWN
 SG_ P01_CONFIG_BYTE_5_RAW m1 : 40|8@1+ (1,0) [0|255] ""  UNKNOWN
 SG_ P02_RELATIVE_TP_SENSOR m2 : 40|8@1+ (0.3921,0) [0|99.9855] "%"  UNKNOWN
 SG_ P03_MAP_SENSOR_V m3 : 40|8@1+ (0.0196,0) [0|4.998] "V"  UNKNOWN
 SG_ P04_OUTPUT_SHAFT_COUNTER_SHAFT_SPEED_RPM m4 : 47|16@0+ (1,0) [0|65535] "rpm"  UNKNOWN
 SG_ P05_APP_SENSOR_B_V m5 : 40|8@1+ (0.0196,0) [0|4.998] "V"  UNKNOWN
 SG_ P06_A_T_C_P_C_SOL_VLV_C_ACTUAL m6 : 40|8@1+ (0.005,0) [0|1.2750000000000001] "A"  UNKNOWN
 SG_ P07_A_T_C_P_C_SOL_VLV_D_COMMAND m7 : 40|8@1+ (0.005,0) [0|1.2750000000000001] "A"  UNKNOWN
 SG_ RSVD_6 m8 : 40|8@1+ (1,0) [0|255] ""  UNKNOWN
 SG_ P01_CONFIG_BYTE_6_RAW m1 : 48|8@1+ (1,0) [0|255] ""  UNKNOWN
 SG_ P02_ECT_SENSOR_V m2 : 48|8@1+ (0.0196,0) [0|4.998] "V"  UNKNOWN
 SG_ P03_MANIFOLD_ABSOLUTE_PRESSURE m3 : 48|8@1+ (1,0) [0|255] "kPa"  UNKNOWN
 SG_ P05_A_T_C_P_C_SOL_VLV_A_COMMAND m5 : 48|8@1+ (0.005,0) [0|1.2750000000000001] "A"  UNKNOWN
 SG_ P06_VEHICLE_SPEED m6 : 48|8@1+ (1,0) [0|255] "km/h"  UNKNOWN
 SG_ P07_LINE_PRESSURE_PRESSURE_SWITCH m7 : 48|1@1+ (1,0) [0|1] ""  UNKNOWN
 SG_ RSVD_7 m8 : 48|8@1+ (1,0) [0|255] ""  UNKNOWN
 SG_ P07_TRANSMISSION_FLUID_PRESSURE_SWITCH_B m7 : 49|1@1+ (1,0) [0|1] ""  UNKNOWN
 SG_ P07_TRANSMISSION_FLUID_PRESSURE_SWITCH_A m7 : 50|1@1+ (1,0) [0|1] ""  UNKNOWN
 SG_ P07_6TH_PRESSURE_SWITCH m7 : 51|1@1+ (1,0) [0|1] ""  UNKNOWN
 SG_ P07_5TH_PRESSURE_SWITCH m7 : 52|1@1+ (1,0) [0|1] ""  UNKNOWN
 SG_ P07_4TH_PRESSURE_SWITCH m7 : 53|1@1+ (1,0) [0|1] ""  UNKNOWN
 SG_ P07_3RD_PRESSURE_SWITCH m7 : 54|1@1+ (1,0) [0|1] ""  UNKNOWN
 SG_ P07_2ND_PRESSURE_SWITCH m7 : 55|1@1+ (1,0) [0|1] ""  UNKNOWN
 SG_ CHECKSUM : 56|4@1+ (1,0) [0|15] ""  UNKNOWN
 SG_ COUNTER : 60|2@1+ (1,0) [0|3] ""  UNKNOWN
 SG_ PROTOCOL_FLAGS : 62|2@1+ (1,0) [0|3] ""  UNKNOWN
VAL_ 1039 P07_2ND_PRESSURE_SWITCH 0 "OFF" 1 "ON" ;
VAL_ 1039 P07_3RD_PRESSURE_SWITCH 0 "OFF" 1 "ON" ;
VAL_ 1039 P07_4TH_PRESSURE_SWITCH 0 "OFF" 1 "ON" ;
VAL_ 1039 P07_5TH_PRESSURE_SWITCH 0 "OFF" 1 "ON" ;
VAL_ 1039 P07_6TH_PRESSURE_SWITCH 0 "OFF" 1 "ON" ;
VAL_ 1039 P07_TRANSMISSION_FLUID_PRESSURE_SWITCH_A 0 "OFF" 1 "ON" ;
VAL_ 1039 P07_TRANSMISSION_FLUID_PRESSURE_SWITCH_B 0 "OFF" 1 "ON" ;
VAL_ 1039 P07_LINE_PRESSURE_PRESSURE_SWITCH 0 "OFF" 1 "ON" ;
VAL_ 1039 P07_A_T_SHIFT_SOL_VLV_A 0 "OFF" 1 "ON" ;
VAL_ 1039 P07_A_T_SHIFT_SOL_VLV_B 0 "OFF" 1 "ON" ;
VAL_ 1039 P07_A_T_SHIFT_SOL_VLV_C 0 "OFF" 1 "ON" ;
VAL_ 1039 P07_A_T_SHIFT_SOL_VLV_D 0 "OFF" 1 "ON" ;
VAL_ 1039 P07_A_T_SHIFT_SOL_VLV_E 0 "OFF" 1 "ON" ;
VAL_ 1039 P07_SHIFT_SOLENOID_VALVE_F 0 "OFF" 1 "ON" ;
VAL_ 1039 P07_SHIFT_SOLENOID_VALVE_G 0 "OFF" 1 "ON" ;
VAL_ 1039 P07_LINE_PRESSURE_SOL_VLV_A 0 "OFF" 1 "ON" ;
SG_MUL_VAL_ 1039 UNKNOWN_1 MULTIPLEX_PAGE 0-0;
SG_MUL_VAL_ 1039 P01_CONFIG_BYTE_1_RAW MULTIPLEX_PAGE 1-1;
SG_MUL_VAL_ 1039 P02_ENGINE_SPEED MULTIPLEX_PAGE 2-2;
SG_MUL_VAL_ 1039 P03_ENGINE_COOLANT_TEMPERATURE MULTIPLEX_PAGE 3-3;
SG_MUL_VAL_ 1039 P04_BARO_SENSOR_V MULTIPLEX_PAGE 4-4;
SG_MUL_VAL_ 1039 P05_INPUT_SHAFT_MAINSHAFT_SPEED_RPM MULTIPLEX_PAGE 5-5;
SG_MUL_VAL_ 1039 P06_A_T_C_P_C_SOL_VLV_A_ACTUAL MULTIPLEX_PAGE 6-6;
SG_MUL_VAL_ 1039 P07_LINE_PRESSURE_SOL_VLV_A MULTIPLEX_PAGE 7-7;
SG_MUL_VAL_ 1039 RSVD_1 MULTIPLEX_PAGE 8-15;
SG_MUL_VAL_ 1039 P07_SHIFT_SOLENOID_VALVE_G MULTIPLEX_PAGE 7-7;
SG_MUL_VAL_ 1039 P07_SHIFT_SOLENOID_VALVE_F MULTIPLEX_PAGE 7-7;
SG_MUL_VAL_ 1039 P07_A_T_SHIFT_SOL_VLV_E MULTIPLEX_PAGE 7-7;
SG_MUL_VAL_ 1039 P07_A_T_SHIFT_SOL_VLV_D MULTIPLEX_PAGE 7-7;
SG_MUL_VAL_ 1039 P07_A_T_SHIFT_SOL_VLV_C MULTIPLEX_PAGE 7-7;
SG_MUL_VAL_ 1039 P07_A_T_SHIFT_SOL_VLV_B MULTIPLEX_PAGE 7-7;
SG_MUL_VAL_ 1039 P07_A_T_SHIFT_SOL_VLV_A MULTIPLEX_PAGE 7-7;
SG_MUL_VAL_ 1039 UNKNOWN_2 MULTIPLEX_PAGE 0-0;
SG_MUL_VAL_ 1039 P01_CONFIG_BYTE_2_RAW MULTIPLEX_PAGE 1-1;
SG_MUL_VAL_ 1039 P02_OUTPUT_SHAFT_COUNTER_SHAFT_SPEED MULTIPLEX_PAGE 2-2;
SG_MUL_VAL_ 1039 P03_BATTERY_VOLTAGE MULTIPLEX_PAGE 3-3;
SG_MUL_VAL_ 1039 P04_ATMOSPHERIC_PRESSURE MULTIPLEX_PAGE 4-4;
SG_MUL_VAL_ 1039 P06_A_T_C_P_C_SOL_VLV_B_COMMAND MULTIPLEX_PAGE 6-6;
SG_MUL_VAL_ 1039 P07_ATF_TEMP_SENSOR_V MULTIPLEX_PAGE 7-7;
SG_MUL_VAL_ 1039 RSVD_2 MULTIPLEX_PAGE 8-15;
SG_MUL_VAL_ 1039 P01_CONFIG_BYTE_3_RAW MULTIPLEX_PAGE 1-1;
SG_MUL_VAL_ 1039 P02_INPUT_SHAFT_MAINSHAFT_SPEED MULTIPLEX_PAGE 2-2;
SG_MUL_VAL_ 1039 P03_SHIFT_CONTROL MULTIPLEX_PAGE 3-3;
SG_MUL_VAL_ 1039 P04_ENGINE_SPEED MULTIPLEX_PAGE 4-4;
SG_MUL_VAL_ 1039 P05_APP_SENSOR MULTIPLEX_PAGE 5-5;
SG_MUL_VAL_ 1039 P06_A_T_C_P_C_SOL_VLV_B_ACTUAL MULTIPLEX_PAGE 6-6;
SG_MUL_VAL_ 1039 P07_ATF_TEMPERATURE MULTIPLEX_PAGE 7-7;
SG_MUL_VAL_ 1039 RSVD_3 MULTIPLEX_PAGE 8-15;
SG_MUL_VAL_ 1039 UNKNOWN_3 MULTIPLEX_PAGE 0-0;
SG_MUL_VAL_ 1039 P01_CONFIG_BYTE_4_RAW MULTIPLEX_PAGE 1-1;
SG_MUL_VAL_ 1039 P02_TP_SENSOR_1 MULTIPLEX_PAGE 2-2;
SG_MUL_VAL_ 1039 UNKNOWN_4 MULTIPLEX_PAGE 3-3;
SG_MUL_VAL_ 1039 P05_APP_SENSOR_A_V MULTIPLEX_PAGE 5-5;
SG_MUL_VAL_ 1039 P06_A_T_C_P_C_SOL_VLV_C_COMMAND MULTIPLEX_PAGE 6-6;
SG_MUL_VAL_ 1039 P07_A_T_C_P_C_SOL_VLV_D_ACTUAL MULTIPLEX_PAGE 7-7;
SG_MUL_VAL_ 1039 RSVD_4 MULTIPLEX_PAGE 8-15;
SG_MUL_VAL_ 1039 RSVD_5 MULTIPLEX_PAGE 0-0;
SG_MUL_VAL_ 1039 P01_CONFIG_BYTE_5_RAW MULTIPLEX_PAGE 1-1;
SG_MUL_VAL_ 1039 P02_RELATIVE_TP_SENSOR MULTIPLEX_PAGE 2-2;
SG_MUL_VAL_ 1039 P03_MAP_SENSOR_V MULTIPLEX_PAGE 3-3;
SG_MUL_VAL_ 1039 P04_OUTPUT_SHAFT_COUNTER_SHAFT_SPEED_RPM MULTIPLEX_PAGE 4-4;
SG_MUL_VAL_ 1039 P05_APP_SENSOR_B_V MULTIPLEX_PAGE 5-5;
SG_MUL_VAL_ 1039 P06_A_T_C_P_C_SOL_VLV_C_ACTUAL MULTIPLEX_PAGE 6-6;
SG_MUL_VAL_ 1039 P07_A_T_C_P_C_SOL_VLV_D_COMMAND MULTIPLEX_PAGE 7-7;
SG_MUL_VAL_ 1039 RSVD_6 MULTIPLEX_PAGE 8-15;
SG_MUL_VAL_ 1039 P01_CONFIG_BYTE_6_RAW MULTIPLEX_PAGE 1-1;
SG_MUL_VAL_ 1039 P02_ECT_SENSOR_V MULTIPLEX_PAGE 2-2;
SG_MUL_VAL_ 1039 P03_MANIFOLD_ABSOLUTE_PRESSURE MULTIPLEX_PAGE 3-3;
SG_MUL_VAL_ 1039 P05_A_T_C_P_C_SOL_VLV_A_COMMAND MULTIPLEX_PAGE 5-5;
SG_MUL_VAL_ 1039 P06_VEHICLE_SPEED MULTIPLEX_PAGE 6-6;
SG_MUL_VAL_ 1039 P07_LINE_PRESSURE_PRESSURE_SWITCH MULTIPLEX_PAGE 7-7;
SG_MUL_VAL_ 1039 RSVD_7 MULTIPLEX_PAGE 8-15;
SG_MUL_VAL_ 1039 P07_TRANSMISSION_FLUID_PRESSURE_SWITCH_B MULTIPLEX_PAGE 7-7;
SG_MUL_VAL_ 1039 P07_TRANSMISSION_FLUID_PRESSURE_SWITCH_A MULTIPLEX_PAGE 7-7;
SG_MUL_VAL_ 1039 P07_6TH_PRESSURE_SWITCH MULTIPLEX_PAGE 7-7;
SG_MUL_VAL_ 1039 P07_5TH_PRESSURE_SWITCH MULTIPLEX_PAGE 7-7;
SG_MUL_VAL_ 1039 P07_4TH_PRESSURE_SWITCH MULTIPLEX_PAGE 7-7;
SG_MUL_VAL_ 1039 P07_3RD_PRESSURE_SWITCH MULTIPLEX_PAGE 7-7;
SG_MUL_VAL_ 1039 P07_2ND_PRESSURE_SWITCH MULTIPLEX_PAGE 7-7;

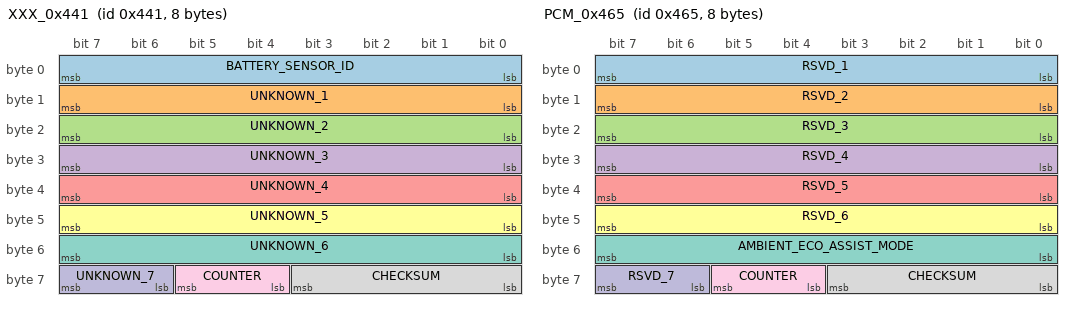
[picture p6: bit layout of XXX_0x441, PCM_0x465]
BO_ 1089 XXX_0x441: 8 PCM
 SG_ BATTERY_SENSOR_ID : 0|8@1+ (1,0) [0|255] ""  UNKNOWN
 SG_ UNKNOWN_1 : 8|8@1+ (1,0) [0|255] ""  UNKNOWN
 SG_ UNKNOWN_2 : 16|8@1+ (1,0) [0|255] ""  UNKNOWN
 SG_ UNKNOWN_3 : 24|8@1+ (1,0) [0|255] ""  UNKNOWN
 SG_ UNKNOWN_4 : 32|8@1+ (1,0) [0|255] ""  UNKNOWN
 SG_ UNKNOWN_5 : 40|8@1+ (1,0) [0|255] ""  UNKNOWN
 SG_ UNKNOWN_6 : 48|8@1+ (1,0) [0|255] ""  UNKNOWN
 SG_ CHECKSUM : 56|4@1+ (1,0) [0|15] ""  UNKNOWN
 SG_ COUNTER : 60|2@1+ (1,0) [0|3] ""  UNKNOWN
 SG_ UNKNOWN_7 : 62|2@1+ (1,0) [0|3] ""  UNKNOWN

BO_ 1108 XXX_0x454: 8 PCM
 SG_ RETAINED_MODEL_QUANTITY_RAW : 0|8@1+ (1,0) [0|255] ""  UNKNOWN
 SG_ BARO_DISPLAY_CODE_RAW : 8|8@1+ (1,0) [0|255] ""  UNKNOWN
 SG_ UNKNOWN_1 : 16|4@1+ (1,0) [0|15] ""  UNKNOWN
 SG_ BAROMETRIC_SENSOR_FAULT_AGGREGATE : 20|1@1+ (1,0) [0|1] ""  UNKNOWN
 SG_ SIGNED_STATE_BIT5_RAW : 21|1@1+ (1,0) [0|1] ""  UNKNOWN
 SG_ MODEL_HOLD_ACTIVE_RAW : 22|1@1+ (1,0) [0|1] ""  UNKNOWN
 SG_ STATUS_BIT_1 : 23|1@1+ (1,0) [0|1] ""  UNKNOWN
 SG_ SCALED_MODEL_QUANTITY_RAW : 31|16@0+ (1,0) [0|65535] ""  UNKNOWN
 SG_ RSVD_1 : 40|8@1+ (1,0) [0|255] ""  UNKNOWN
 SG_ ELECTRICAL_MONITOR_SECONDARY_RAW : 48|1@1+ (1,0) [0|1] ""  UNKNOWN
 SG_ STATUS_BIT_2 : 49|1@1+ (1,0) [0|1] ""  UNKNOWN
 SG_ STATUS_BIT_3 : 50|1@1+ (1,0) [0|1] ""  UNKNOWN
 SG_ ELECTRICAL_MONITOR_PRIMARY_RAW : 51|1@1+ (1,0) [0|1] ""  UNKNOWN
 SG_ RSVD_2 : 52|1@1+ (1,0) [0|1] ""  UNKNOWN
 SG_ RSVD_3 : 53|1@1+ (1,0) [0|1] ""  UNKNOWN
 SG_ RSVD_4 : 54|1@1+ (1,0) [0|1] ""  UNKNOWN
 SG_ MONITOR_HOLD_RAW : 55|1@1+ (1,0) [0|1] ""  UNKNOWN
 SG_ CHECKSUM : 56|4@1+ (1,0) [0|15] ""  UNKNOWN
 SG_ COUNTER : 60|2@1+ (1,0) [0|3] ""  UNKNOWN
 SG_ RSVD_5 : 62|2@1+ (1,0) [0|3] ""  UNKNOWN

BO_ 1125 PCM_0x465: 8 PCM
 SG_ RSVD_1 : 0|8@1+ (1,0) [0|255] ""  UNKNOWN
 SG_ RSVD_2 : 8|8@1+ (1,0) [0|255] ""  UNKNOWN
 SG_ RSVD_3 : 16|8@1+ (1,0) [0|255] ""  UNKNOWN
 SG_ RSVD_4 : 24|8@1+ (1,0) [0|255] ""  UNKNOWN
 SG_ RSVD_5 : 32|8@1+ (1,0) [0|255] ""  UNKNOWN
 SG_ RSVD_6 : 40|8@1+ (1,0) [0|255] ""  UNKNOWN
 SG_ AMBIENT_ECO_ASSIST_MODE : 48|8@1+ (1,0) [0|255] ""  UNKNOWN
 SG_ CHECKSUM : 56|4@1+ (1,0) [0|15] ""  UNKNOWN
 SG_ COUNTER : 60|2@1+ (1,0) [0|3] ""  UNKNOWN
 SG_ RSVD_7 : 62|2@1+ (1,0) [0|3] ""  UNKNOWN
VAL_ 1125 AMBIENT_ECO_ASSIST_MODE 1 "WHITE" 2 "LIGHT_GREEN" 3 "GREEN" ;
